# peci register map
Vendor: Texas Instruments
Peripheral module from a debugger description file (folder sc4e129bnczad).
Registers are 32-bit, read-write, no defined reset value unless marked. A register's access mark holds for its fields unless they carry their own. Offsets are as the file gives them; lines under a group give offsets from that group; [hi:lo] are bit positions; {n}, {i} and the like mark numbered series; 'fields as' and 'values as' point back to an identical list; <NAME> marks a mode.

## PECI0 — PECI register addresses
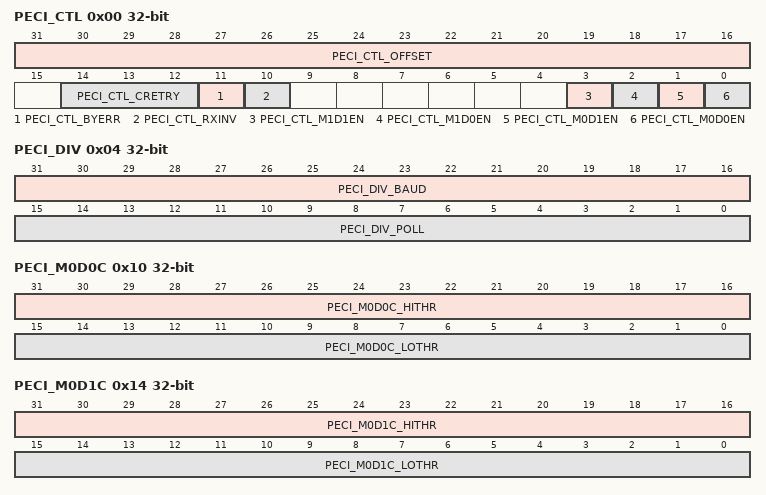
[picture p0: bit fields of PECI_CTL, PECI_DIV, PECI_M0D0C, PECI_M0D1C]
0x00 PECI_CTL — PECI Control
  [31:16] PECI_CTL_OFFSET — Offset Value
  [14:12] PECI_CTL_CRETRY — Number of Controller Retries
  [11] PECI_CTL_BYERR — Timing Negotiation Error Bypass
  [10] PECI_CTL_RXINV — Invert PECI RX Input
  [3] PECI_CTL_M1D1EN — Enable Microprocessor 1 and Domain 1
  [2] PECI_CTL_M1D0EN — Enable Microprocessor 1 and Domain 0
  [1] PECI_CTL_M0D1EN — Enable Microprocessor 0 and Domain 1
  [0] PECI_CTL_M0D0EN — Enable Microprocessor 0 and Domain 0
0x04 PECI_DIV — PECI Poll-Rate Divider
  [31:16] PECI_DIV_BAUD — Baud Rate
  [15:0] PECI_DIV_POLL — Counter for Inter-Poll Delay
0x10 PECI_M0D0C — PECI Microprocessor 0 / Domain 0 Control
  [31:16] PECI_M0D0C_HITHR — High Threshold
  [15:0] PECI_M0D0C_LOTHR — Low Threshold
0x14 PECI_M0D1C — PECI Microprocessor 0 / Domain 1 Control
  [31:16] PECI_M0D1C_HITHR — High Threshold
  [15:0] PECI_M0D1C_LOTHR — Low Threshold
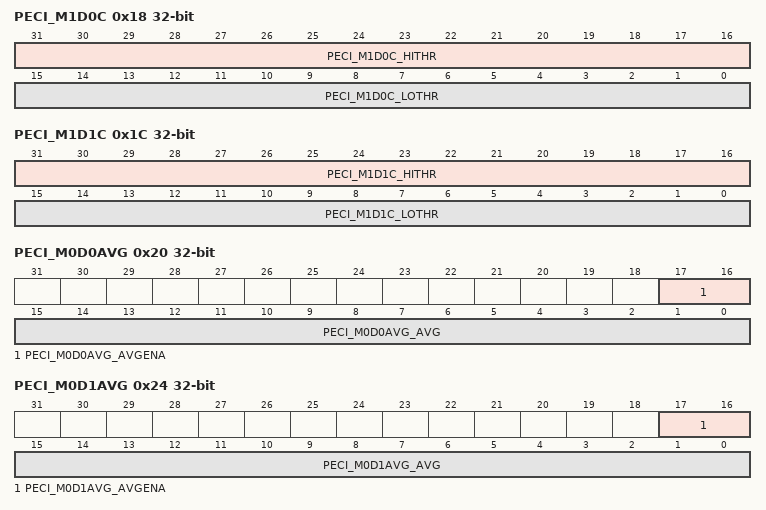
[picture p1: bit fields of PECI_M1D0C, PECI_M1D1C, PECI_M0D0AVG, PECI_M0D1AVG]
0x18 PECI_M1D0C — PECI Microprocessor 1 / Domain 0 Control
  [31:16] PECI_M1D0C_HITHR — High Threshold
  [15:0] PECI_M1D0C_LOTHR — Low Threshold
0x1C PECI_M1D1C — PECI Microprocessor 1 / Domain 1 Control
  [31:16] PECI_M1D1C_HITHR — High Threshold
  [15:0] PECI_M1D1C_LOTHR — Low Threshold
0x20 PECI_M0D0AVG — PECI Microprocessor 0 / Domain 0 Average
  [17:16] PECI_M0D0AVG_AVGENA — Averaging Enable
    0=PECI_M0D0AVG_AVGENA_DIS (Averaging disabled); 1=Modified moving average of 2; 2=Modified moving average of 4; 3=Modified moving average of 8
  [15:0] PECI_M0D0AVG_AVG — Average Temperature Data Value
0x24 PECI_M0D1AVG — PECI Microprocessor 0 / Domain 1 Average
  [17:16] PECI_M0D1AVG_AVGENA — Averaging Enable
    0=PECI_M0D1AVG_AVGENA_DIS (Averaging disabled); 1=Modified moving average of 2; 2=Modified moving average of 4; 3=Modified moving average of 8
  [15:0] PECI_M0D1AVG_AVG — Average Temperature Data Value
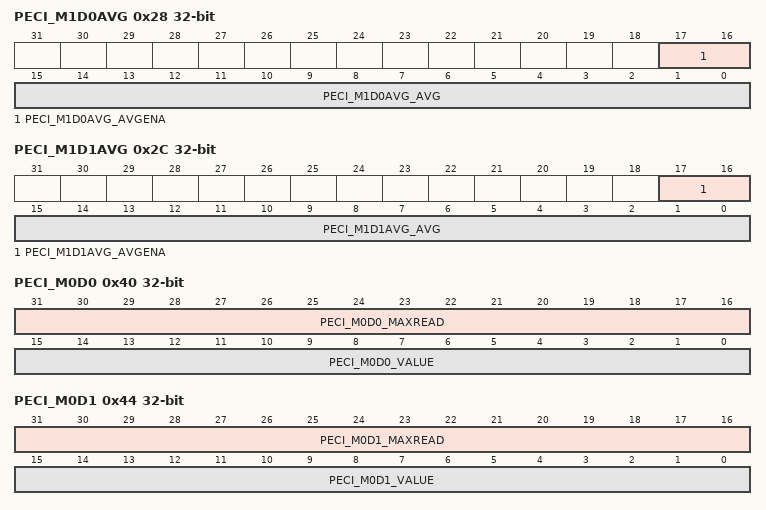
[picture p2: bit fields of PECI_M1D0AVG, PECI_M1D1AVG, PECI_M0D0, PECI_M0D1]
0x28 PECI_M1D0AVG — PECI Microprocessor 1 / Domain 0 Average
  [17:16] PECI_M1D0AVG_AVGENA — Averaging Enable
    0=PECI_M1D0AVG_AVGENA_DIS (Averaging disabled); 1=Modified moving average of 2; 2=Modified moving average of 4; 3=Modified moving average of 8
  [15:0] PECI_M1D0AVG_AVG — Average Temperature Data Value
0x2C PECI_M1D1AVG — PECI Microprocessor 1 / Domain 1 Average
  [17:16] PECI_M1D1AVG_AVGENA — Averaging Enable
    0=PECI_M1D1AVG_AVGENA_DIS (Averaging disabled); 1=Modified moving average of 2; 2=Modified moving average of 4; 3=Modified moving average of 8
  [15:0] PECI_M1D1AVG_AVG — Average Temperature Data Value
0x40 PECI_M0D0 — PECI Microprocessor 0 / Domain 0 Value
  [31:16] PECI_M0D0_MAXREAD — Highest Value Read
  [15:0] PECI_M0D0_VALUE — Last Value Read
    0x81F9=PECI_M0D0_VALUE_MCRCTX (Microprocessor abort CRC error on transmitted data); 0x81FA=PECI_M0D0_VALUE_CRCRX (CRC error on received data); 0x81FB=PECI_M0D0_VALUE_CRCTX (CRC error on transmitted data); 0x81FC=PECI_M0D0_VALUE_NEG (Negotiation error); 0x81FD=PECI_M0D0_VALUE_TO (Timeout error)
0x44 PECI_M0D1 — PECI Microprocessor 0 / Domain 1 Value
  [31:16] PECI_M0D1_MAXREAD — Highest Value Read
  [15:0] PECI_M0D1_VALUE — Last Value Read
    0x81F9=PECI_M0D1_VALUE_MCRCTX (Microprocessor abort CRC error on transmitted data); 0x81FA=PECI_M0D1_VALUE_CRCRX (CRC error on received data); 0x81FB=PECI_M0D1_VALUE_CRCTX (CRC error on transmitted data); 0x81FC=PECI_M0D1_VALUE_NEG (Negotiation error); 0x81FD=PECI_M0D1_VALUE_TO (Timeout error)
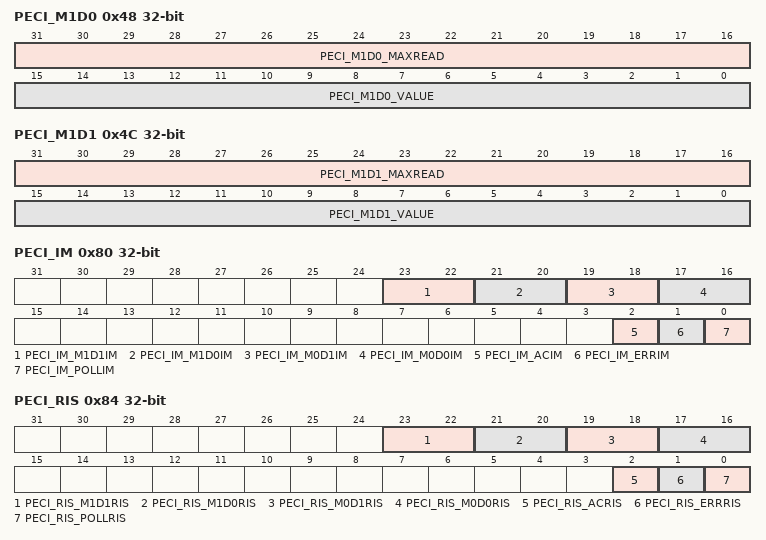
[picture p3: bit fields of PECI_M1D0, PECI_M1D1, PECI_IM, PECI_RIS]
0x48 PECI_M1D0 — PECI Microprocessor 1 / Domain 0 Value
  [31:16] PECI_M1D0_MAXREAD — Highest Value Read
  [15:0] PECI_M1D0_VALUE — Last Value Read
    0x81F9=PECI_M1D0_VALUE_MCRCTX (Microprocessor abort CRC error on transmitted data); 0x81FA=PECI_M1D0_VALUE_CRCRX (CRC error on received data); 0x81FB=PECI_M1D0_VALUE_CRCTX (CRC error on transmitted data); 0x81FC=PECI_M1D0_VALUE_NEG (Negotiation error); 0x81FD=PECI_M1D0_VALUE_TO (Timeout error)
0x4C PECI_M1D1 — PECI Microprocessor 1 / Domain 1 Value
  [31:16] PECI_M1D1_MAXREAD — Highest Value Read
  [15:0] PECI_M1D1_VALUE — Last Value Read
    0x81F9=PECI_M1D1_VALUE_MCRCTX (Microprocessor abort CRC error on transmitted data); 0x81FA=PECI_M1D1_VALUE_CRCRX (CRC error on received data); 0x81FB=PECI_M1D1_VALUE_CRCTX (CRC error on transmitted data); 0x81FC=PECI_M1D1_VALUE_NEG (Negotiation error); 0x81FD=PECI_M1D1_VALUE_TO (Timeout error)
0x80 PECI_IM — PECI Interrupt Mask
  [23:22] PECI_IM_M1D1IM — Microprocessor 1 and Domain 1 Interrupt Mode
    1=PECI_IM_M1D1IM_HIGH (Interrupt when crossing above high threshold); 2=PECI_IM_M1D1IM_CROSSUP (Interrupt when crossing above either threshold); 3=PECI_IM_M1D1IM_CROSSANY (Interrupt when crossing either threshold in either direction)
  [21:20] PECI_IM_M1D0IM — Microprocessor 1 and Domain 0 Interrupt Mode
  [19:18] PECI_IM_M0D1IM — Microprocessor 0 and Domain 1 Interrupt Mode
  [17:16] PECI_IM_M0D0IM — Microprocessor 0 and Domain 0 Interrupt Mode
  [2] PECI_IM_ACIM — Advanced Command Interrupt Mask
  [1] PECI_IM_ERRIM — Polling Error Detected Interrupt Mask
  [0] PECI_IM_POLLIM — Poll Completed Interrupt Mask
0x84 PECI_RIS ro — PECI Raw Interrupt Status
  [23:22] PECI_RIS_M1D1RIS — Microprocessor 1 and Domain 1 Raw Interrupt Status
  [21:20] PECI_RIS_M1D0RIS — Microprocessor 1 and Domain 0 Raw Interrupt Status
  [19:18] PECI_RIS_M0D1RIS — Microprocessor 0 and Domain 1 Raw Interrupt Status
  [17:16] PECI_RIS_M0D0RIS — Microprocessor 0 and Domain 0 Raw Interrupt Status
  [2] PECI_RIS_ACRIS — Advanced Command Raw Interrupt Status
  [1] PECI_RIS_ERRRIS — Polling Error Detected Raw Interrupt Status
  [0] PECI_RIS_POLLRIS — Poll Completed Raw Interrupt Status
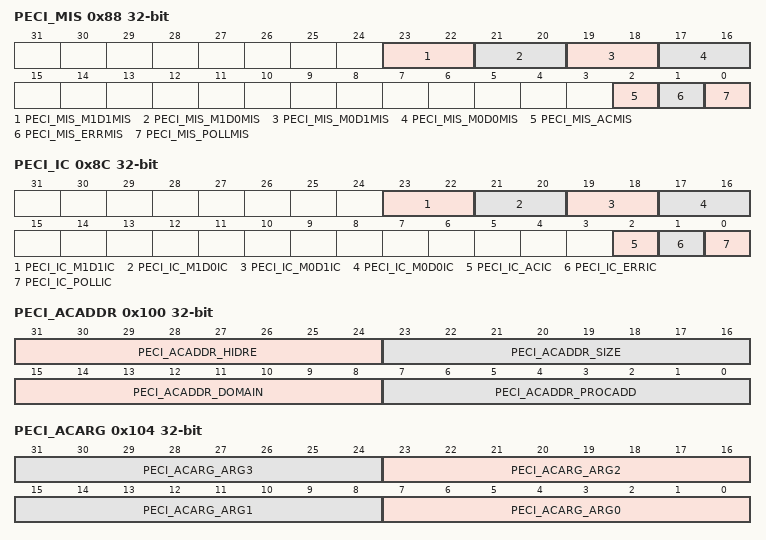
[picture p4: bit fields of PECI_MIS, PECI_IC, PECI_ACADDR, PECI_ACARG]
0x88 PECI_MIS ro — PECI Masked Interrupt Status
  [23:22] PECI_MIS_M1D1MIS — Microprocessor 1 and Domain 1 Masked Interrupt Status
  [21:20] PECI_MIS_M1D0MIS — Microprocessor 1 and Domain 0 Masked Interrupt Status
  [19:18] PECI_MIS_M0D1MIS — Microprocessor 0 and Domain 1 Masked Interrupt Status
  [17:16] PECI_MIS_M0D0MIS — Microprocessor 0 and Domain 0 Masked Interrupt Status
  [2] PECI_MIS_ACMIS — Advanced Command Masked Interrupt Status
  [1] PECI_MIS_ERRMIS — Polling Error Detected Masked Interrupt Status
  [0] PECI_MIS_POLLMIS — Poll Completed Masked Interrupt Status
0x8C PECI_IC wo — PECI Interrupt Clear
  [23:22] PECI_IC_M1D1IC — Microprocessor 1 and Domain 1 Interrupt Clear
  [21:20] PECI_IC_M1D0IC — Microprocessor 1 and Domain 0 Interrupt Clear
  [19:18] PECI_IC_M0D1IC — Microprocessor 0 and Domain 1 Interrupt Clear
  [17:16] PECI_IC_M0D0IC — Microprocessor 0 and Domain 0 Interrupt Clear
  [2] PECI_IC_ACIC — Advanced Command Interrupt Clear
  [1] PECI_IC_ERRIC — Polling Error Detected Interrupt Clear
  [0] PECI_IC_POLLIC — Poll Completed Interrupt Clear
0x100 PECI_ACADDR — PECI Advanced Command Address
  [31:24] PECI_ACADDR_HIDRE — HostID and Retry
  [23:16] PECI_ACADDR_SIZE — Data Size
  [15:8] PECI_ACADDR_DOMAIN — Domain Select
  [7:0] PECI_ACADDR_PROCADD — Processor Address
0x104 PECI_ACARG — PECI Advanced Command Argument
  [8n+7:8n] PECI_ACARG_ARG{n} (n=0..3) — Argument {n}
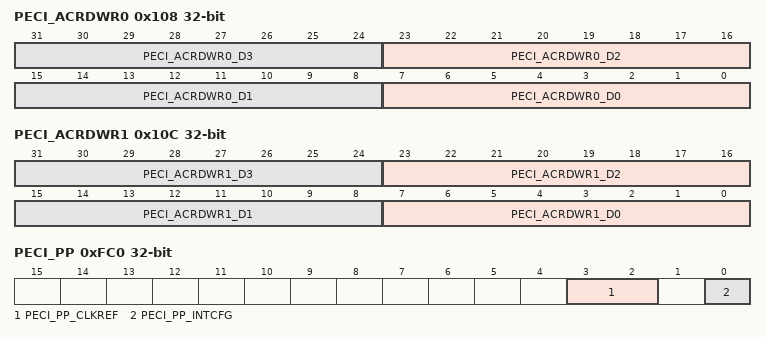
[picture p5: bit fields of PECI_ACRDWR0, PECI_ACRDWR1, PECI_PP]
0x108 PECI_ACRDWR0 — PECI Advanced Command Data 0
  [8n+7:8n] PECI_ACRDWR0_D{n} (n=0..3) — Data {n}
0x10C PECI_ACRDWR1 — PECI Advanced Command Data 1
  [8n+7:8n] PECI_ACRDWR1_D{n} (n=0..3) — Data {n}
0x110 PECI_ACCMD — PECI Advanced Command
  [7:0] PECI_ACCMD_CMD — Base Command
0x114 PECI_ACCODE ro — PECI Advanced Command Completion Code
  [31:0] PECI_ACCODE_CODE — Signed Completion Code
0x204 PECI_BAUD — PECI Current Baud Value
  [15:0] PECI_BAUD_NBAUD — Baud Value
0xFC0 PECI_PP ro — PECI Peripheral Properties
  [3:2] PECI_PP_CLKREF — PECI Clock Reference
    0=PECI_PP_CLKREF_SYSCLK (System clock); 1=PECI_PP_CLKREF_PIOSC (PIOSC)
  [0] PECI_PP_INTCFG — PECI Interface Configuration
